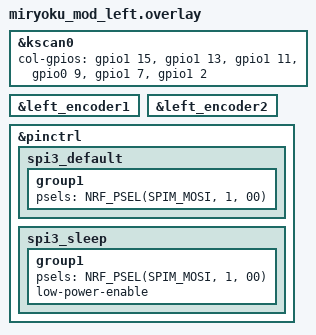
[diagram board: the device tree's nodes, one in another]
#include "miryoku_mod.dtsi"

&kscan0 {
    col-gpios
    = <&gpio1 15 (GPIO_ACTIVE_HIGH | GPIO_PULL_DOWN)> // col1 in the schematic
    , <&gpio1 13 (GPIO_ACTIVE_HIGH | GPIO_PULL_DOWN)> // col2 in the schematic
    , <&gpio1 11 (GPIO_ACTIVE_HIGH | GPIO_PULL_DOWN)> // col3 in the schematic
    , <&gpio0 9  (GPIO_ACTIVE_HIGH | GPIO_PULL_DOWN)> // col4 in the schematic
    , <&gpio1 7  (GPIO_ACTIVE_HIGH | GPIO_PULL_DOWN)> // col5 in the schematic
    , <&gpio1 2  (GPIO_ACTIVE_HIGH | GPIO_PULL_DOWN)> // col6 in the schematic
    ;
};

&left_encoder1 {
    status = "okay";
};
&left_encoder2 {
    status = "okay";
};


&pinctrl {
    spi3_default: spi3_default {
        group1 {
            psels = <NRF_PSEL(SPIM_MOSI, 1, 00)>;
        };
    };

    spi3_sleep: spi3_sleep {
        group1 {
            psels = <NRF_PSEL(SPIM_MOSI, 1, 00)>;
            low-power-enable;
        };
    };
};
